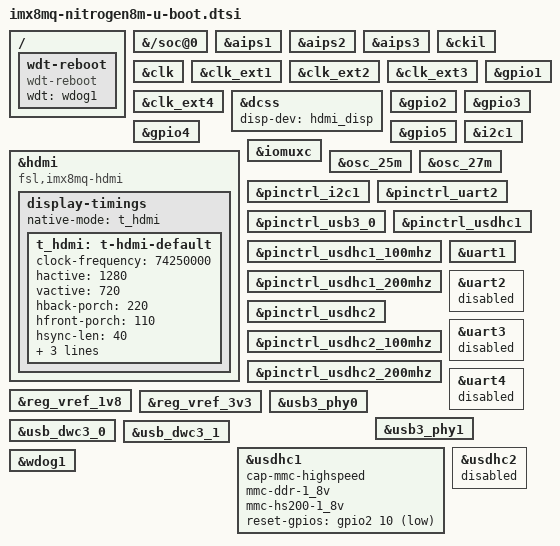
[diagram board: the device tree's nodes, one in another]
// SPDX-License-Identifier: GPL-2.0+
/*
 * Copyright 2019 NXP
 */
#include "imx8mq-u-boot.dtsi"

/ {
	wdt-reboot {
		compatible = "wdt-reboot";
		wdt = <&wdog1>;
		bootph-pre-ram;
	};
};

&{/soc@0} {
	bootph-all;
	bootph-pre-ram;
};

&aips1 {
	bootph-pre-ram;
	bootph-all;
};

&aips2 {
	bootph-pre-ram;
};

&aips3 {
	bootph-pre-ram;
};

&ckil {
	bootph-pre-ram;
	bootph-all;
};

&clk {
	bootph-pre-ram;
	bootph-all;
	/delete-property/ assigned-clocks;
	/delete-property/ assigned-clock-parents;
	/delete-property/ assigned-clock-rates;
};

&clk_ext1 {
	bootph-pre-ram;
	bootph-all;
};

&clk_ext2 {
	bootph-pre-ram;
	bootph-all;
};

&clk_ext3 {
	bootph-pre-ram;
	bootph-all;
};

&clk_ext4 {
	bootph-pre-ram;
	bootph-all;
};

&dcss {
	disp-dev = "hdmi_disp";
};

&gpio1 {
	bootph-pre-ram;
};

&gpio2 {
	bootph-pre-ram;
};

&gpio3 {
	bootph-pre-ram;
};

&gpio4 {
	bootph-pre-ram;
};

&gpio5 {
	bootph-pre-ram;
};

&hdmi {
	compatible = "fsl,imx8mq-hdmi";

	display-timings {
		native-mode = <&t_hdmi>;

		t_hdmi: t-hdmi-default {
			clock-frequency = <74250000>;
			hactive = <1280>;
			vactive = <720>;
			hback-porch = <220>;
			hfront-porch = <110>;
			hsync-len = <40>;
			vback-porch = <20>;
			vfront-porch = <5>;
			vsync-len = <5>;
		};
	};
};

&i2c1 {
	bootph-pre-ram;
};

&iomuxc {
	bootph-pre-ram;
};

&osc_25m {
	bootph-pre-ram;
	bootph-all;
};

&osc_27m {
	bootph-pre-ram;
	bootph-all;
};

&pinctrl_i2c1 {
	bootph-pre-ram;
};

&pinctrl_uart2 {
	bootph-pre-ram;
};

&pinctrl_usb3_0 {
	bootph-pre-ram;
};

&pinctrl_usdhc1 {
	bootph-pre-ram;
};

&pinctrl_usdhc1_100mhz {
	bootph-pre-ram;
};

&pinctrl_usdhc1_200mhz {
	bootph-pre-ram;
};

&pinctrl_usdhc2 {
	bootph-pre-ram;
};

&pinctrl_usdhc2_100mhz {
	bootph-pre-ram;
};

&pinctrl_usdhc2_200mhz {
	bootph-pre-ram;
};

&reg_vref_1v8 {
	bootph-pre-ram;
};

&reg_vref_3v3 {
	bootph-pre-ram;
};

&uart1 {
	bootph-pre-ram;
};

&uart2 {
	status = "disabled";
};

&uart3 {
	status = "disabled";
};

&uart4 {
	status = "disabled";
};

&usb3_phy0 {
	bootph-pre-ram;
};

&usb3_phy1 {
	bootph-pre-ram;
};

&usb_dwc3_0 {
	bootph-pre-ram;
};

&usb_dwc3_1 {
	bootph-pre-ram;
};

&usdhc1 {
	cap-mmc-highspeed;
	mmc-ddr-1_8v;
	mmc-hs200-1_8v;
	reset-gpios = <&gpio2 10 GPIO_ACTIVE_LOW>;
	bootph-pre-ram;
};

&usdhc2 {
	status = "disabled";
};

&wdog1 {
	bootph-pre-ram;
};
